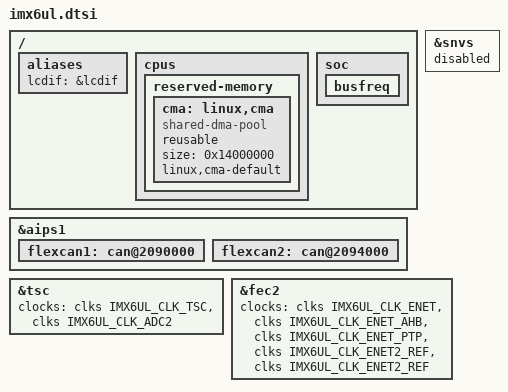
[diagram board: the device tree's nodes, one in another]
#include "../nxp/imx/imx6ull.dtsi"

/ {
	aliases {
		lcdif = &lcdif;
	};
	cpus {
		#address-cells = <1>;
		#size-cells = <0>;
        reserved-memory {
                #address-cells = <1>;
                #size-cells = <0>;
                ranges;

                /* global autoconfigured region for contiguous allocations */
                cma:linux,cma {
                        compatible = "shared-dma-pool";
                        reusable;
                        size = <0x14000000>;
                        linux,cma-default;
                };
        };
	};

	soc {
		busfreq: busfreq {};
	};
};

&aips1 {
	flexcan1:can@2090000 {};
	flexcan2:can@2094000 {};
};

&tsc {
	clocks = <&clks IMX6UL_CLK_TSC>,
		 <&clks IMX6UL_CLK_ADC2>;
};

&snvs {
	status = "disabled";
};

&fec2 {
				clocks = <&clks IMX6UL_CLK_ENET>,
					 <&clks IMX6UL_CLK_ENET_AHB>,
					 <&clks IMX6UL_CLK_ENET_PTP>,
					 <&clks IMX6UL_CLK_ENET2_REF>,
					 <&clks IMX6UL_CLK_ENET2_REF>;
				clock-names = "ipg", "ahb", "ptp",
					      "enet_clk_ref", "enet_out";
};

